VERSION ""

NS_ :

BS_:

BU_: ESP32S3 UNO_R3

BO_ 256 SPEED_RPM: 8 UNO_R3
 SG_ VEHICLE_SPEED : 0|16@1+ (1,0) [0|250] "km/h" ESP32S3
 SG_ ENGINE_RPM : 16|16@1+ (1,0) [0|8000] "rpm" ESP32S3

BO_ 512 THROTTLE_LOAD: 8 UNO_R3
 SG_ THROTTLE_POS : 0|8@1+ (0.392157,0) [0|100] "%" ESP32S3
 SG_ ENGINE_LOAD : 8|8@1+ (0.392157,0) [0|100] "%" ESP32S3

BO_ 768 COOLANT_TEMP: 8 UNO_R3
 SG_ COOLANT_TEMP_C : 0|8@1+ (1,-40) [-40|215] "degC" ESP32S3

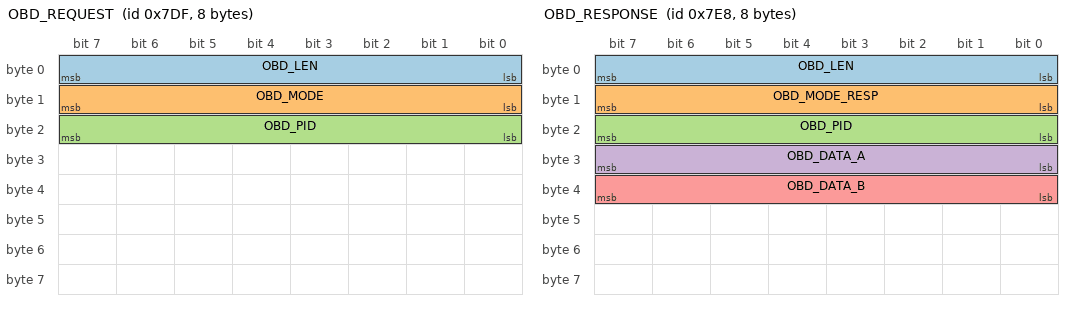
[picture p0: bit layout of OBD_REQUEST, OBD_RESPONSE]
BO_ 2015 OBD_REQUEST: 8 ESP32S3
 SG_ OBD_LEN : 0|8@1+ (1,0) [0|8] "" UNO_R3
 SG_ OBD_MODE : 8|8@1+ (1,0) [0|255] "" UNO_R3
 SG_ OBD_PID : 16|8@1+ (1,0) [0|255] "" UNO_R3

BO_ 2024 OBD_RESPONSE: 8 UNO_R3
 SG_ OBD_LEN : 0|8@1+ (1,0) [0|8] "" ESP32S3
 SG_ OBD_MODE_RESP : 8|8@1+ (1,0) [0|255] "" ESP32S3
 SG_ OBD_PID : 16|8@1+ (1,0) [0|255] "" ESP32S3
 SG_ OBD_DATA_A : 24|8@1+ (1,0) [0|255] "" ESP32S3
 SG_ OBD_DATA_B : 32|8@1+ (1,0) [0|255] "" ESP32S3

BO_ 16 PROFILE_CMD: 8 ESP32S3
 SG_ PROFILE_ID : 0|8@1+ (1,0) [0|3] "" UNO_R3
